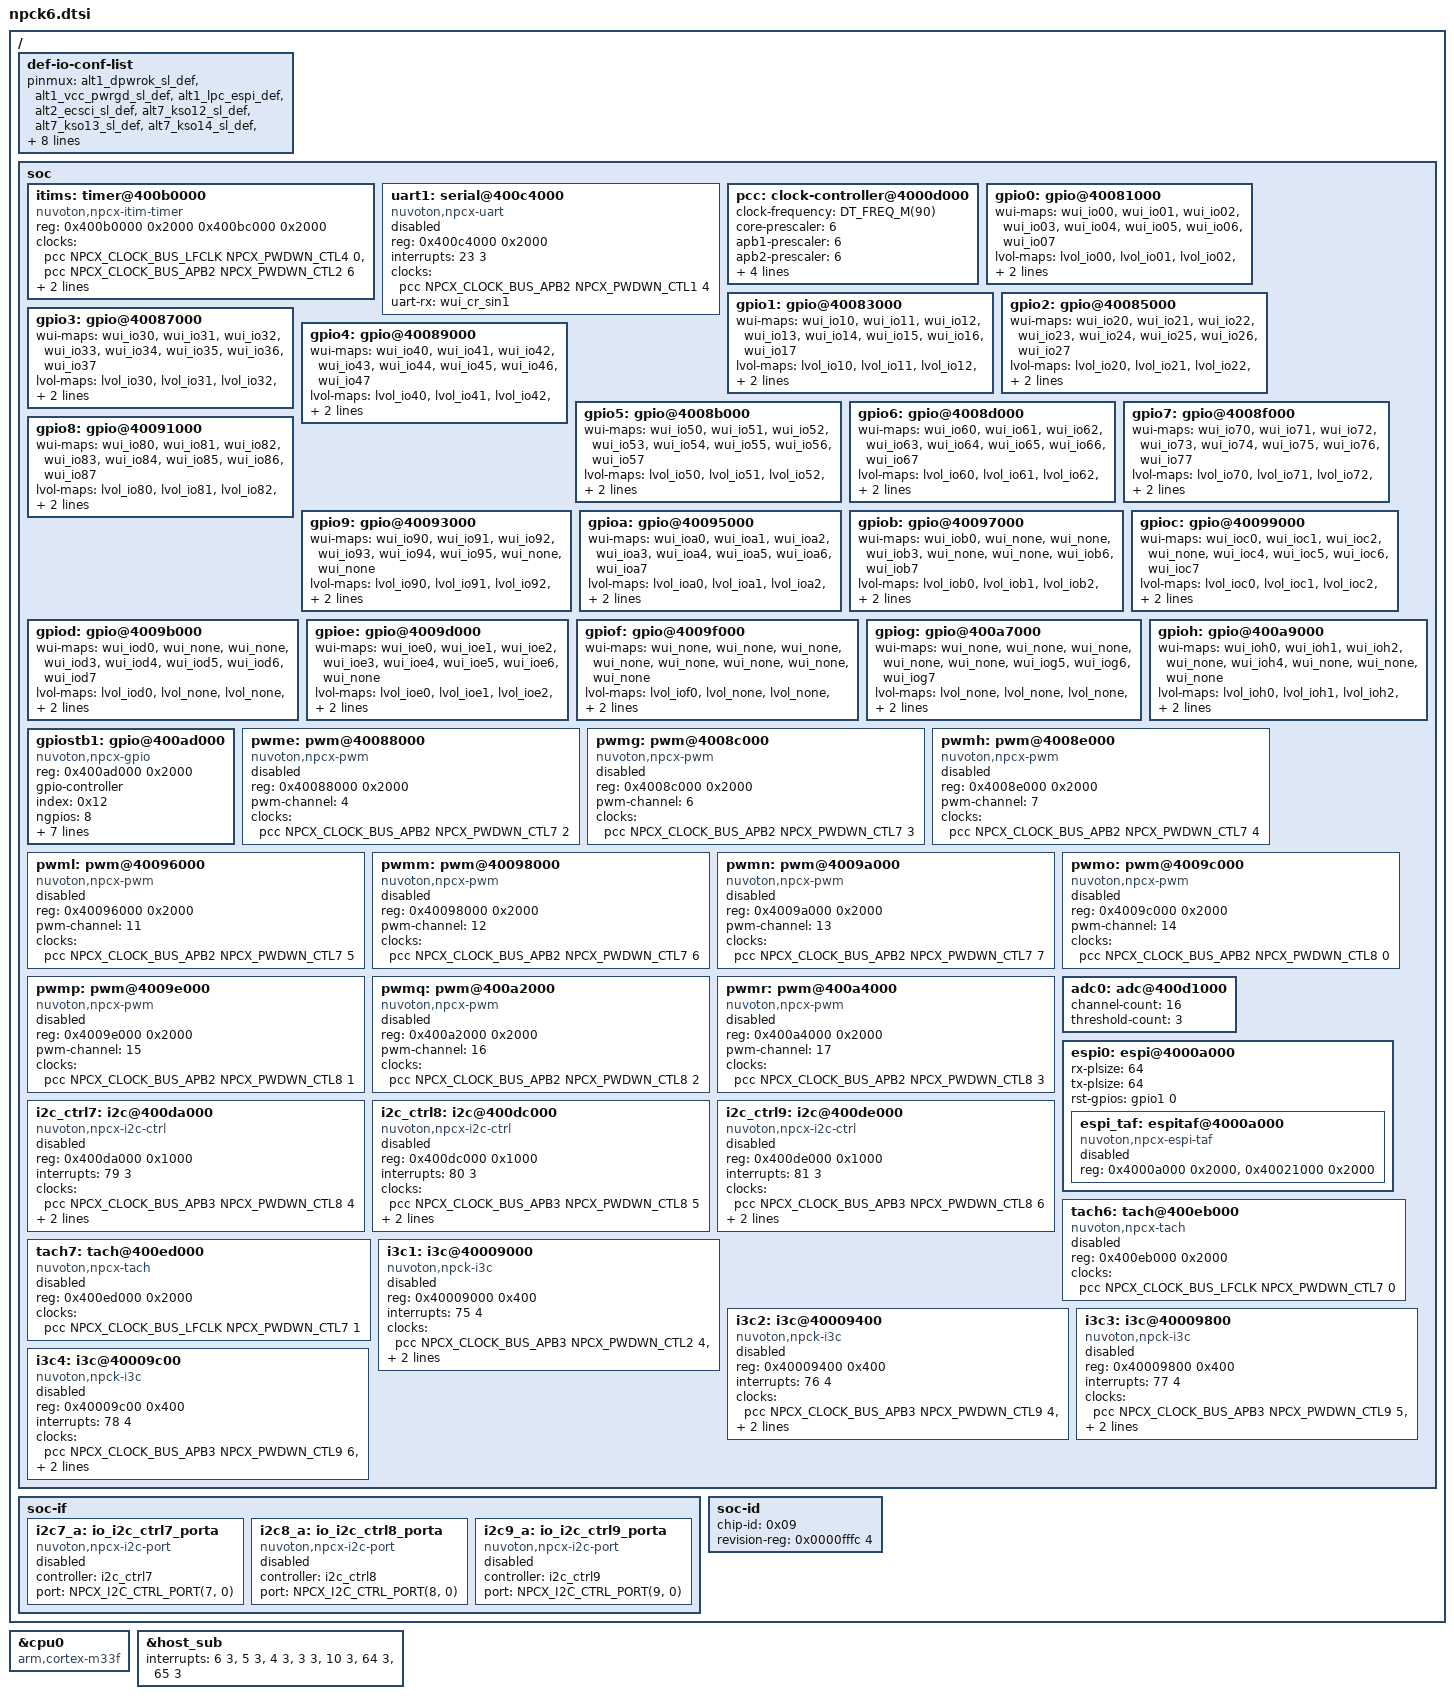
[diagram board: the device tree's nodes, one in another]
/*
 * Copyright (c) 2026 Nuvoton Technology Corporation.
 *
 * SPDX-License-Identifier: Apache-2.0
 */

#include <arm/armv8-m.dtsi>

/* NPCK6 series pinmux mapping table */
#include "npck6/npck6-alts-map.dtsi"
/* NPCK6 series mapping table between MIWU wui bits and source device */
#include "npck6/npck6-miwus-wui-map.dtsi"
/* NPCK6 series mapping table between MIWU groups and interrupts */
#include "npck6/npck6-miwus-int-map.dtsi"
/* NPCK6 series eSPI VW mapping table */
#include "npck6/npck6-espi-vws-map.dtsi"
/* NPCK6 series low-voltage io controls mapping table */
#include "npck6/npck6-lvol-ctrl-map.dtsi"

/* Device tree declarations of npcx soc family */
#include "npck.dtsi"

/ {
	def-io-conf-list {
		pinmux = <&alt1_dpwrok_sl_def
			  &alt1_vcc_pwrgd_sl_def
			  &alt1_lpc_espi_def
			  &alt2_ecsci_sl_def
			  &alt7_kso12_sl_def
			  &alt7_kso13_sl_def
			  &alt7_kso14_sl_def
			  &alt7_kso15_sl_def
			  &alt8_kbrst_sl_def
			  &alt9_no_ksi0_ksi1_ksi2_ksi3_sl
			  &alt9_no_ksi4_ksi5_sl
			  &alt9_no_ksi6_ksi7_sl
			  &alt9_no_kso0_kso1_kso2_kso3_sl
			  &alt9_no_kso4_kso5_kso6_kso7_sl
			  &alt9_no_kso8_kso9_sl
			  &alt9_no_kso10_kso11_sl
			  &altf_psl_in0_en_def
			  &altf_psl_in1_en_def>;
	};

	soc {
		/* Specific soc devices in npck6 series */
		itims: timer@400b0000 {
			compatible = "nuvoton,npcx-itim-timer";
			reg = <0x400b0000 0x2000
			       0x400bc000 0x2000>;
			reg-names = "evt_itim", "sys_itim";
			clocks = <&pcc NPCX_CLOCK_BUS_LFCLK NPCX_PWDWN_CTL4 0
				  &pcc NPCX_CLOCK_BUS_APB2 NPCX_PWDWN_CTL2 6>;
			interrupts = <29 1>; /* Event timer interrupt */
			clock-frequency = <15000000>; /* Set for SYS_CLOCK_HW_CYCLES_PER_SEC */
		};

		uart1: serial@400c4000 {
			compatible = "nuvoton,npcx-uart", "nuvoton,npcx-uart-npckn";
			reg = <0x400c4000 0x2000>;
			interrupts = <23 3>;
			clocks = <&pcc NPCX_CLOCK_BUS_APB2 NPCX_PWDWN_CTL1 4>;
			uart-rx = <&wui_cr_sin1>;
			status = "disabled";
		};

		/* Default clock and power settings in npck6 series */
		/*
		 * [ToDo] SHA PD can be disabled; the system will transition to
		 * using SHA3 moving forward.
		 */
		pcc: clock-controller@4000d000 {
			clock-frequency = <DT_FREQ_M(90)>; /* OFMCLK runs at 90MHz */
			core-prescaler = <6>; /* CORE_CLK runs at 15MHz */
			apb1-prescaler = <6>; /* APB1_CLK runs at 15MHz */
			apb2-prescaler = <6>; /* APB2_CLK runs at 15MHz */
			apb3-prescaler = <6>; /* APB3_CLK runs at 15MHz */
			ram-pd-depth = <40>; /* Valid bit-depth of RAM_PDn reg */
			pwdwn-ctl-val = <0xe7 /* Start with PWDWN_CTL0 */
					 0xfb /* No FIU_PD */
					 0xff
					 0x7f /* No GDMA */
					 0xb7 /* No N2JTAG/SMB_DMA */
					 0xfa /* No CCD/PSL */
					 0x07 /* No eSPI/SAH3/AES/SHA/PKA */
					 0xff
					 0x7f
					 0x7f>;
		};

		/* Wake-up input source mapping for GPIOs in npck6 series */
		gpio0: gpio@40081000 {
			wui-maps = <&wui_io00 &wui_io01 &wui_io02 &wui_io03
				    &wui_io04 &wui_io05 &wui_io06 &wui_io07>;

			lvol-maps = <&lvol_io00 &lvol_io01 &lvol_io02 &lvol_io03
				     &lvol_io04 &lvol_io05 &lvol_io06 &lvol_io07>;
		};

		gpio1: gpio@40083000 {
			wui-maps = <&wui_io10 &wui_io11 &wui_io12 &wui_io13
				    &wui_io14 &wui_io15 &wui_io16 &wui_io17>;

			lvol-maps = <&lvol_io10 &lvol_io11 &lvol_io12 &lvol_io13
				     &lvol_io14 &lvol_io15 &lvol_io16 &lvol_io17>;
		};

		gpio2: gpio@40085000 {
			wui-maps = <&wui_io20 &wui_io21 &wui_io22 &wui_io23
				    &wui_io24 &wui_io25 &wui_io26 &wui_io27>;

			lvol-maps = <&lvol_io20 &lvol_io21 &lvol_io22 &lvol_io23
				     &lvol_io24 &lvol_io25 &lvol_io26 &lvol_io27>;
		};

		gpio3: gpio@40087000 {
			wui-maps = <&wui_io30 &wui_io31 &wui_io32 &wui_io33
				    &wui_io34 &wui_io35 &wui_io36 &wui_io37>;

			lvol-maps = <&lvol_io30 &lvol_io31 &lvol_io32 &lvol_io33
				     &lvol_io34 &lvol_io35 &lvol_io36 &lvol_io37>;
		};

		gpio4: gpio@40089000 {
			wui-maps = <&wui_io40 &wui_io41 &wui_io42 &wui_io43
				    &wui_io44 &wui_io45 &wui_io46 &wui_io47>;

			lvol-maps = <&lvol_io40 &lvol_io41 &lvol_io42 &lvol_io43
				     &lvol_io44 &lvol_io45 &lvol_io46 &lvol_io47>;
		};

		gpio5: gpio@4008b000 {
			wui-maps = <&wui_io50 &wui_io51 &wui_io52 &wui_io53
				    &wui_io54 &wui_io55 &wui_io56 &wui_io57>;

			lvol-maps = <&lvol_io50 &lvol_io51 &lvol_io52 &lvol_io53
				     &lvol_io54 &lvol_io55 &lvol_io56 &lvol_io57>;
		};

		gpio6: gpio@4008d000 {
			wui-maps = <&wui_io60 &wui_io61 &wui_io62 &wui_io63
				    &wui_io64 &wui_io65 &wui_io66 &wui_io67>;

			lvol-maps = <&lvol_io60 &lvol_io61 &lvol_io62 &lvol_io63
				     &lvol_io64 &lvol_io65 &lvol_io66 &lvol_io67>;
		};

		gpio7: gpio@4008f000 {
			wui-maps = <&wui_io70 &wui_io71 &wui_io72 &wui_io73
				    &wui_io74 &wui_io75 &wui_io76 &wui_io77>;

			lvol-maps = <&lvol_io70 &lvol_io71 &lvol_io72 &lvol_io73
				     &lvol_io74 &lvol_io75 &lvol_io76 &lvol_io77>;
		};

		gpio8: gpio@40091000 {
			wui-maps = <&wui_io80 &wui_io81 &wui_io82 &wui_io83
				    &wui_io84 &wui_io85 &wui_io86 &wui_io87>;

			lvol-maps = <&lvol_io80 &lvol_io81 &lvol_io82 &lvol_io83
				     &lvol_io84 &lvol_io85 &lvol_io86 &lvol_io87>;
		};

		gpio9: gpio@40093000 {
			wui-maps = <&wui_io90 &wui_io91 &wui_io92 &wui_io93
				    &wui_io94 &wui_io95 &wui_none &wui_none>;

			lvol-maps = <&lvol_io90 &lvol_io91 &lvol_io92 &lvol_io93
				     &lvol_io94 &lvol_io95 &lvol_none &lvol_none>;
		};

		gpioa: gpio@40095000 {
			wui-maps = <&wui_ioa0 &wui_ioa1 &wui_ioa2 &wui_ioa3
				    &wui_ioa4 &wui_ioa5 &wui_ioa6 &wui_ioa7>;

			lvol-maps = <&lvol_ioa0 &lvol_ioa1 &lvol_ioa2 &lvol_ioa3
				     &lvol_ioa4 &lvol_ioa5 &lvol_ioa6 &lvol_ioa7>;
		};

		gpiob: gpio@40097000 {
			wui-maps = <&wui_iob0 &wui_none &wui_none &wui_iob3
				    &wui_none &wui_none &wui_iob6 &wui_iob7>;

			lvol-maps = <&lvol_iob0 &lvol_iob1 &lvol_iob2 &lvol_iob3
				     &lvol_iob4 &lvol_iob5 &lvol_iob6 &lvol_iob7>;
		};

		gpioc: gpio@40099000 {
			wui-maps = <&wui_ioc0 &wui_ioc1 &wui_ioc2 &wui_none
				    &wui_ioc4 &wui_ioc5 &wui_ioc6 &wui_ioc7>;

			lvol-maps = <&lvol_ioc0 &lvol_ioc1 &lvol_ioc2 &lvol_ioc3
				     &lvol_ioc4 &lvol_ioc5 &lvol_ioc6 &lvol_ioc7>;
		};

		gpiod: gpio@4009b000 {
			wui-maps = <&wui_iod0 &wui_none &wui_none &wui_iod3
				    &wui_iod4 &wui_iod5 &wui_iod6 &wui_iod7>;

			lvol-maps = <&lvol_iod0 &lvol_none &lvol_none &lvol_iod3
				     &lvol_iod4 &lvol_iod5 &lvol_iod6 &lvol_iod7>;
		};

		gpioe: gpio@4009d000 {
			wui-maps = <&wui_ioe0 &wui_ioe1 &wui_ioe2 &wui_ioe3
				    &wui_ioe4 &wui_ioe5 &wui_ioe6 &wui_none>;

			lvol-maps = <&lvol_ioe0 &lvol_ioe1 &lvol_ioe2 &lvol_ioe3
				     &lvol_ioe4 &lvol_ioe5 &lvol_ioe6 &lvol_none>;
		};

		gpiof: gpio@4009f000 {
			wui-maps = <&wui_none &wui_none &wui_none &wui_none
				    &wui_none &wui_none &wui_none &wui_none>;

			lvol-maps = <&lvol_iof0 &lvol_none &lvol_none &lvol_none
				     &lvol_none &lvol_none &lvol_iof6 &lvol_iof7>;
		};

		gpiog: gpio@400a7000 {
			wui-maps = <&wui_none &wui_none &wui_none &wui_none
				    &wui_none &wui_iog5 &wui_iog6 &wui_iog7>;

			lvol-maps = <&lvol_none &lvol_none &lvol_none &lvol_none
				     &lvol_none &lvol_iog5 &lvol_iog6 &lvol_iog7>;
		};

		gpioh: gpio@400a9000 {
			wui-maps = <&wui_ioh0 &wui_ioh1 &wui_ioh2 &wui_none
				    &wui_ioh4 &wui_none &wui_none &wui_none>;

			lvol-maps = <&lvol_ioh0 &lvol_ioh1 &lvol_ioh2 &lvol_none
				     &lvol_ioh4 &lvol_none &lvol_none &lvol_none>;
		};

		gpiostb1: gpio@400ad000 {
			compatible = "nuvoton,npcx-gpio";
			reg = <0x400ad000 0x2000>;
			gpio-controller;
			index = <0x12>;
			ngpios = <8>;
			#gpio-cells = <2>;
			wui-maps = <&wui_none &wui_io_stb11_psl_in0
				    &wui_io_stb12_psl_in1 &wui_io_stb13_psl_in2
				    &wui_io_stb14_psl_in3 &wui_none
				    &wui_io_stb16_psl_in5 &wui_none>;

			lvol-maps = <&lvol_none &lvol_io_stb11 &lvol_io_stb12 &lvol_io_stb13
				     &lvol_io_stb14 &lvol_none &lvol_io_stb16 &lvol_io_stb17>;
		};

		pwme: pwm@40088000 {
			compatible = "nuvoton,npcx-pwm";
			reg = <0x40088000 0x2000>;
			pwm-channel = <4>;
			clocks = <&pcc NPCX_CLOCK_BUS_APB2 NPCX_PWDWN_CTL7 2>;
			#pwm-cells = <3>;
			status = "disabled";
		};

		pwmg: pwm@4008c000 {
			compatible = "nuvoton,npcx-pwm";
			reg = <0x4008c000 0x2000>;
			pwm-channel = <6>;
			clocks = <&pcc NPCX_CLOCK_BUS_APB2 NPCX_PWDWN_CTL7 3>;
			#pwm-cells = <3>;
			status = "disabled";
		};

		pwmh: pwm@4008e000 {
			compatible = "nuvoton,npcx-pwm";
			reg = <0x4008e000 0x2000>;
			pwm-channel = <7>;
			clocks = <&pcc NPCX_CLOCK_BUS_APB2 NPCX_PWDWN_CTL7 4>;
			#pwm-cells = <3>;
			status = "disabled";
		};

		pwml: pwm@40096000 {
			compatible = "nuvoton,npcx-pwm";
			reg = <0x40096000 0x2000>;
			pwm-channel = <11>;
			clocks = <&pcc NPCX_CLOCK_BUS_APB2 NPCX_PWDWN_CTL7 5>;
			#pwm-cells = <3>;
			status = "disabled";
		};

		pwmm: pwm@40098000 {
			compatible = "nuvoton,npcx-pwm";
			reg = <0x40098000 0x2000>;
			pwm-channel = <12>;
			clocks = <&pcc NPCX_CLOCK_BUS_APB2 NPCX_PWDWN_CTL7 6>;
			#pwm-cells = <3>;
			status = "disabled";
		};

		pwmn: pwm@4009a000 {
			compatible = "nuvoton,npcx-pwm";
			reg = <0x4009a000 0x2000>;
			pwm-channel = <13>;
			clocks = <&pcc NPCX_CLOCK_BUS_APB2 NPCX_PWDWN_CTL7 7>;
			#pwm-cells = <3>;
			status = "disabled";
		};

		pwmo: pwm@4009c000 {
			compatible = "nuvoton,npcx-pwm";
			reg = <0x4009c000 0x2000>;
			pwm-channel = <14>;
			clocks = <&pcc NPCX_CLOCK_BUS_APB2 NPCX_PWDWN_CTL8 0>;
			#pwm-cells = <3>;
			status = "disabled";
		};

		pwmp: pwm@4009e000 {
			compatible = "nuvoton,npcx-pwm";
			reg = <0x4009e000 0x2000>;
			pwm-channel = <15>;
			clocks = <&pcc NPCX_CLOCK_BUS_APB2 NPCX_PWDWN_CTL8 1>;
			#pwm-cells = <3>;
			status = "disabled";
		};

		pwmq: pwm@400a2000 {
			compatible = "nuvoton,npcx-pwm";
			reg = <0x400a2000 0x2000>;
			pwm-channel = <16>;
			clocks = <&pcc NPCX_CLOCK_BUS_APB2 NPCX_PWDWN_CTL8 2>;
			#pwm-cells = <3>;
			status = "disabled";
		};

		pwmr: pwm@400a4000 {
			compatible = "nuvoton,npcx-pwm";
			reg = <0x400a4000 0x2000>;
			pwm-channel = <17>;
			clocks = <&pcc NPCX_CLOCK_BUS_APB2 NPCX_PWDWN_CTL8 3>;
			#pwm-cells = <3>;
			status = "disabled";
		};

		/* ADC0 comparator configuration in npck6 series */
		adc0: adc@400d1000 {
			channel-count = <16>;
			threshold-count = <3>;
		};

		espi0: espi@4000a000 {
			rx-plsize = <64>;
			tx-plsize = <64>;

			rst-gpios = <&gpio1 0 0>;

			#address-cells = <1>;
			#size-cells = <1>;

			espi_taf: espitaf@4000a000 {
				compatible = "nuvoton,npcx-espi-taf";
				reg = <0x4000a000 0x2000>,
				      <0x40021000 0x2000>;
				reg-names = "saf", "fiu1";
				status = "disabled";
			};
		};

		i2c_ctrl7: i2c@400da000 {
			compatible = "nuvoton,npcx-i2c-ctrl";
			reg = <0x400da000 0x1000>;
			interrupts = <79 3>;
			clocks = <&pcc NPCX_CLOCK_BUS_APB3 NPCX_PWDWN_CTL8 4>;
			/* SMB4 and SMB7 share the smae WUI */
			smb-wui = <&wui_smb4>;
			dma-driven;
			status = "disabled";
		};

		i2c_ctrl8: i2c@400dc000 {
			compatible = "nuvoton,npcx-i2c-ctrl";
			reg = <0x400dc000 0x1000>;
			interrupts = <80 3>;
			clocks = <&pcc NPCX_CLOCK_BUS_APB3 NPCX_PWDWN_CTL8 5>;
			/* SMB5 and SMB8 share the smae WUI */
			smb-wui = <&wui_smb5>;
			dma-driven;
			status = "disabled";
		};

		i2c_ctrl9: i2c@400de000 {
			compatible = "nuvoton,npcx-i2c-ctrl";
			reg = <0x400de000 0x1000>;
			interrupts = <81 3>;
			clocks = <&pcc NPCX_CLOCK_BUS_APB3 NPCX_PWDWN_CTL8 6>;
			/* SMB6 and SMB9 share the smae WUI */
			smb-wui = <&wui_smb6>;
			dma-driven;
			status = "disabled";
		};

		tach6: tach@400eb000 {
			compatible = "nuvoton,npcx-tach";
			reg = <0x400eb000 0x2000>;
			clocks = <&pcc NPCX_CLOCK_BUS_LFCLK NPCX_PWDWN_CTL7 0>;
			status = "disabled";
		};

		tach7: tach@400ed000 {
			compatible = "nuvoton,npcx-tach";
			reg = <0x400ed000 0x2000>;
			clocks = <&pcc NPCX_CLOCK_BUS_LFCLK NPCX_PWDWN_CTL7 1>;
			status = "disabled";
		};

		i3c1: i3c@40009000 {
			compatible = "nuvoton,npck-i3c";
			reg = <0x40009000 0x400>;
			interrupts = <75 4>;
			/* clk[0]: I3C bus clock, clk[1]: register and timeout reference clock */
			clock-names = "bus-clk", "reg-clk";
			clocks = <&pcc NPCX_CLOCK_BUS_APB3 NPCX_PWDWN_CTL2 4>,
				 <&pcc NPCX_CLOCK_BUS_APB3 0 0>;
			#address-cells = <3>;
			#size-cells = <0>;
			instance-id = <0x10>;
			status = "disabled";
		};

		i3c2: i3c@40009400 {
			compatible = "nuvoton,npck-i3c";
			reg = <0x40009400 0x400>;
			interrupts = <76 4>;
			/* clk[0]: I3C source clock, clk[1]: register and timeout reference clock */
			clock-names = "bus-clk", "reg-clk";
			clocks = <&pcc NPCX_CLOCK_BUS_APB3 NPCX_PWDWN_CTL9 4>,
				 <&pcc NPCX_CLOCK_BUS_APB3 0 0>;
			#address-cells = <3>;
			#size-cells = <0>;
			instance-id = <0x20>;
			status = "disabled";
		};

		i3c3: i3c@40009800 {
			compatible = "nuvoton,npck-i3c";
			reg = <0x40009800 0x400>;
			interrupts = <77 4>;
			/* clk[0]: I3C bus clock, clk[1]: register and timeout reference clock */
			clock-names = "bus-clk", "reg-clk";
			clocks = <&pcc NPCX_CLOCK_BUS_APB3 NPCX_PWDWN_CTL9 5>,
				 <&pcc NPCX_CLOCK_BUS_APB3 0 0>;
			#address-cells = <3>;
			#size-cells = <0>;
			/* TODO: should we need it for npck6? */
			instance-id = <0x30>;
			status = "disabled";
		};

		i3c4: i3c@40009c00 {
			compatible = "nuvoton,npck-i3c";
			reg = <0x40009c00 0x400>;
			interrupts = <78 4>;
			/* clk[0]: I3C bus clock, clk[1]: register and timeout reference clock */
			clock-names = "bus-clk", "reg-clk";
			clocks = <&pcc NPCX_CLOCK_BUS_APB3 NPCX_PWDWN_CTL9 6>,
				 <&pcc NPCX_CLOCK_BUS_APB3 0 0>;
			#address-cells = <3>;
			#size-cells = <0>;
			/* TODO: should we need it for npck6? */
			instance-id = <0x40>;
			status = "disabled";
		};
	};

	soc-if {
		i2c7_a: io_i2c_ctrl7_porta {
			compatible = "nuvoton,npcx-i2c-port";
			#address-cells = <1>;
			#size-cells = <0>;
			controller = <&i2c_ctrl7>;
			port = <NPCX_I2C_CTRL_PORT(7, 0)>;
			status = "disabled";
		};

		i2c8_a: io_i2c_ctrl8_porta {
			compatible = "nuvoton,npcx-i2c-port";
			#address-cells = <1>;
			#size-cells = <0>;
			controller = <&i2c_ctrl8>;
			port = <NPCX_I2C_CTRL_PORT(8, 0)>;
			status = "disabled";
		};

		i2c9_a: io_i2c_ctrl9_porta {
			compatible = "nuvoton,npcx-i2c-port";
			#address-cells = <1>;
			#size-cells = <0>;
			controller = <&i2c_ctrl9>;
			port = <NPCX_I2C_CTRL_PORT(9, 0)>;
			status = "disabled";
		};
	};

	soc-id {
		chip-id = <0x09>;
		revision-reg = <0x0000fffc 4>;
	};
};

&cpu0 {
	compatible = "arm,cortex-m33f";
};

&host_sub {
	interrupts = <6 3>, /* KBC Input-Buf-Full (IBF) */
		     <5 3>, /* KBC Output-Buf-Empty (OBE) */
		     <4 3>, /* PMCH Input-Buf-Full (IBF) */
		     <3 3>, /* PMCH Output-Buf-Empty (OBE) */
		     <10 3>, /* Port80 FIFO Not Empty */
		     <64 3>, /* SHM/MBI */
		     <65 3>; /* SHM/MBI2 */
	interrupt-names = "kbc_ibf", "kbc_obe", "pmch_ibf",
			  "pmch_obe", "p80_fifo", "shm_mbi", "shm_mbi2";
};
